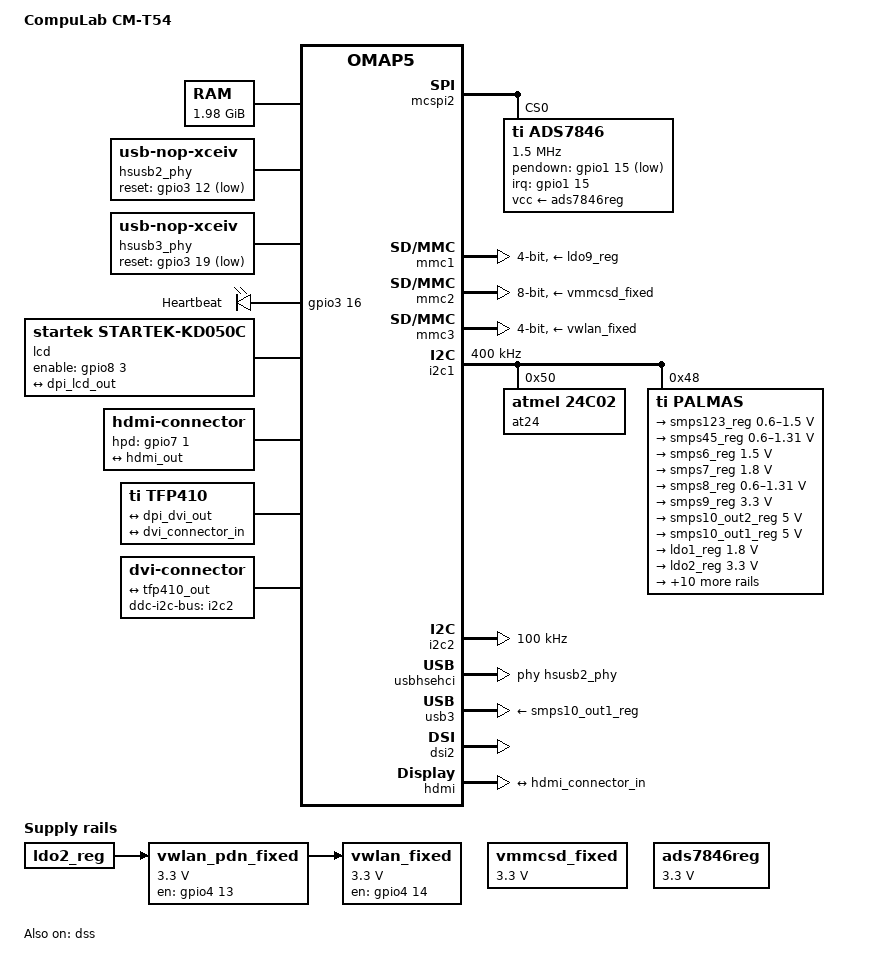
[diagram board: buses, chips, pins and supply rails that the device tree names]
/dts-v1/;
#include "omap5.dtsi"
#include <dt-bindings/interrupt-controller/irq.h>
#include <dt-bindings/interrupt-controller/arm-gic.h>
/ {
	model = "CompuLab CM-T54";
	compatible = "compulab,omap5-cm-t54", "ti,omap5";
	memory@80000000 {
		device_type = "memory";
		reg = <0 0x80000000 0 0x7f000000>;  
	};
	aliases {
		display0 = &hdmi0;
		display1 = &dvi0;
		display2 = &lcd0;
	};
	vmmcsd_fixed: fixed-regulator-mmcsd {
		compatible = "regulator-fixed";
		regulator-name = "vmmcsd_fixed";
		regulator-min-microvolt = <3300000>;
		regulator-max-microvolt = <3300000>;
	};
	vwlan_pdn_fixed: fixed-regulator-vwlan-pdn {
		compatible = "regulator-fixed";
		regulator-name = "vwlan_pdn_fixed";
		regulator-min-microvolt = <3300000>;
		regulator-max-microvolt = <3300000>;
		vin-supply = <&ldo2_reg>;
		gpio = <&gpio4 13 GPIO_ACTIVE_HIGH>;    
		startup-delay-us = <1000>;
		enable-active-high;
	};
	vwlan_fixed: fixed-regulator-vwlan {
		compatible = "regulator-fixed";
		regulator-name = "vwlan_fixed";
		regulator-min-microvolt = <3300000>;
		regulator-max-microvolt = <3300000>;
		vin-supply = <&vwlan_pdn_fixed>;
		gpio = <&gpio4 14 GPIO_ACTIVE_HIGH>;    
		startup-delay-us = <1000>;
		enable-active-high;
	};
	ads7846reg: ads7846-reg {
		compatible = "regulator-fixed";
		regulator-name = "ads7846-reg";
		regulator-min-microvolt = <3300000>;
		regulator-max-microvolt = <3300000>;
	};
	hsusb2_phy: hsusb2-phy-pins {
		compatible = "usb-nop-xceiv";
		reset-gpios = <&gpio3 12 GPIO_ACTIVE_LOW>;  
		#phy-cells = <0>;
	};
	hsusb3_phy: hsusb3_phy {
		compatible = "usb-nop-xceiv";
		reset-gpios = <&gpio3 19 GPIO_ACTIVE_LOW>;  
		#phy-cells = <0>;
	};
	leds {
		compatible = "gpio-leds";
		led1 {
			label = "Heartbeat";
			gpios = <&gpio3 16 GPIO_ACTIVE_HIGH>;  
			linux,default-trigger = "heartbeat";
			default-state = "off";
		};
	};
	lcd0: display {
		compatible = "startek,startek-kd050c", "panel-dpi";
		label = "lcd";
		pinctrl-names = "default";
		pinctrl-0 = <&lcd_pins>;
		enable-gpios = <&gpio8 3 GPIO_ACTIVE_HIGH>;
		panel-timing {
			clock-frequency = <33000000>;
			hactive = <800>;
			vactive = <480>;
			hfront-porch = <40>;
			hback-porch = <40>;
			hsync-len = <43>;
			vback-porch = <29>;
			vfront-porch = <13>;
			vsync-len = <3>;
			hsync-active = <0>;
			vsync-active = <0>;
			de-active = <1>;
			pixelclk-active = <1>;
		};
		port {
			lcd_in: endpoint {
				remote-endpoint = <&dpi_lcd_out>;
			};
		};
	};
	hdmi0: connector0 {
		compatible = "hdmi-connector";
		label = "hdmi";
		type = "a";
		pinctrl-names = "default";
		pinctrl-0 = <&hdmi_conn_pins>;
		hpd-gpios = <&gpio7 1 GPIO_ACTIVE_HIGH>;  
		port {
			hdmi_connector_in: endpoint {
				remote-endpoint = <&hdmi_out>;
			};
		};
	};
	tfp410: encoder0 {
		compatible = "ti,tfp410";
		ports {
			#address-cells = <1>;
			#size-cells = <0>;
			port@0 {
				reg = <0>;
				tfp410_in: endpoint {
					remote-endpoint = <&dpi_dvi_out>;
				};
			};
			port@1 {
				reg = <1>;
				tfp410_out: endpoint {
					remote-endpoint = <&dvi_connector_in>;
				};
			};
		};
	};
	dvi0: connector1 {
		compatible = "dvi-connector";
		label = "dvi";
		digital;
		ddc-i2c-bus = <&i2c2>;
		port {
			dvi_connector_in: endpoint {
				remote-endpoint = <&tfp410_out>;
			};
		};
	};
};
&omap5_pmx_wkup {
	ads7846_pins: ads7846-pins {
		pinctrl-single,pins = <
			OMAP5_IOPAD(0x0042, PIN_INPUT_PULLDOWN | MUX_MODE6)   
		>;
	};
	palmas_sys_nirq_pins: palmas-sys-nirq-pins {
		pinctrl-single,pins = <
			OMAP5_IOPAD(0x068, PIN_INPUT_PULLUP | MUX_MODE0)
		>;
	};
};
&omap5_pmx_core {
	pinctrl-names = "default";
	pinctrl-0 = <
			&led_gpio_pins
			&usbhost_pins
	>;
	led_gpio_pins: led-gpio-pins {
		pinctrl-single,pins = <
			OMAP5_IOPAD(0x00b0, PIN_OUTPUT | MUX_MODE6)  
		>;
	};
	i2c1_pins: i2c1-pins {
		pinctrl-single,pins = <
			OMAP5_IOPAD(0x01f2, PIN_INPUT_PULLUP | MUX_MODE0)  
			OMAP5_IOPAD(0x01f4, PIN_INPUT_PULLUP | MUX_MODE0)  
		>;
	};
	i2c2_pins: i2c2-pins {
		pinctrl-single,pins = <
			OMAP5_IOPAD(0x01b8, PIN_INPUT | MUX_MODE0)  
			OMAP5_IOPAD(0x01ba, PIN_INPUT | MUX_MODE0)  
		>;
	};
	mmc1_pins: mmc1-pins {
		pinctrl-single,pins = <
			OMAP5_IOPAD(0x01e2, PIN_INPUT_PULLUP | MUX_MODE0)  
			OMAP5_IOPAD(0x01e4, PIN_INPUT_PULLUP | MUX_MODE0)  
			OMAP5_IOPAD(0x01e6, PIN_INPUT_PULLUP | MUX_MODE0)  
			OMAP5_IOPAD(0x01e8, PIN_INPUT_PULLUP | MUX_MODE0)  
			OMAP5_IOPAD(0x01ea, PIN_INPUT_PULLUP | MUX_MODE0)  
			OMAP5_IOPAD(0x01ec, PIN_INPUT_PULLUP | MUX_MODE0)  
		>;
	};
	mmc2_pins: mmc2-pins {
		pinctrl-single,pins = <
			OMAP5_IOPAD(0x0040, PIN_INPUT_PULLUP | MUX_MODE0)  
			OMAP5_IOPAD(0x0042, PIN_INPUT_PULLUP | MUX_MODE0)  
			OMAP5_IOPAD(0x0044, PIN_INPUT_PULLUP | MUX_MODE0)  
			OMAP5_IOPAD(0x0046, PIN_INPUT_PULLUP | MUX_MODE0)  
			OMAP5_IOPAD(0x0048, PIN_INPUT_PULLUP | MUX_MODE0)  
			OMAP5_IOPAD(0x004a, PIN_INPUT_PULLUP | MUX_MODE0)  
			OMAP5_IOPAD(0x004c, PIN_INPUT_PULLUP | MUX_MODE0)  
			OMAP5_IOPAD(0x004e, PIN_INPUT_PULLUP | MUX_MODE0)  
			OMAP5_IOPAD(0x0050, PIN_INPUT_PULLUP | MUX_MODE0)  
			OMAP5_IOPAD(0x0052, PIN_INPUT_PULLUP | MUX_MODE0)  
		>;
	};
	mmc3_pins: mmc3-pins {
		pinctrl-single,pins = <
			OMAP5_IOPAD(0x01a4, PIN_INPUT_PULLUP | MUX_MODE0)  
			OMAP5_IOPAD(0x01a6, PIN_INPUT_PULLUP | MUX_MODE0)  
			OMAP5_IOPAD(0x01a8, PIN_INPUT_PULLUP | MUX_MODE0)  
			OMAP5_IOPAD(0x01aa, PIN_INPUT_PULLUP | MUX_MODE0)  
			OMAP5_IOPAD(0x01ac, PIN_INPUT_PULLUP | MUX_MODE0)  
			OMAP5_IOPAD(0x01ae, PIN_INPUT_PULLUP | MUX_MODE0)  
		>;
	};
	wlan_gpios_pins: wlan-gpios-pins {
		pinctrl-single,pins = <
			OMAP5_IOPAD(0x019c, PIN_OUTPUT_PULLDOWN | MUX_MODE6)  
			OMAP5_IOPAD(0x019e, PIN_OUTPUT_PULLDOWN | MUX_MODE6)  
		>;
	};
	usbhost_pins: usbhost-pins {
		pinctrl-single,pins = <
			OMAP5_IOPAD(0x00c4, PIN_INPUT | MUX_MODE0)   
			OMAP5_IOPAD(0x00c6, PIN_INPUT | MUX_MODE0)   
			OMAP5_IOPAD(0x01dc, PIN_INPUT | MUX_MODE0)   
			OMAP5_IOPAD(0x01de, PIN_INPUT | MUX_MODE0)   
			OMAP5_IOPAD(0x00a8, PIN_OUTPUT | MUX_MODE6)  
			OMAP5_IOPAD(0x00b6, PIN_OUTPUT | MUX_MODE6)  
		>;
	};
	dss_hdmi_pins: dss-hdmi-pins {
		pinctrl-single,pins = <
			OMAP5_IOPAD(0x013c, PIN_INPUT | MUX_MODE0)  
			OMAP5_IOPAD(0x0140, PIN_INPUT | MUX_MODE0)  
			OMAP5_IOPAD(0x0142, PIN_INPUT | MUX_MODE0)  
		>;
	};
	lcd_pins: lcd-pins {
		pinctrl-single,pins = <
			OMAP5_IOPAD(0x0172, PIN_OUTPUT_PULLDOWN | MUX_MODE6)  
		>;
	};
	hdmi_conn_pins: hdmi-conn-pins {
		pinctrl-single,pins = <
			OMAP5_IOPAD(0x013e, PIN_INPUT | MUX_MODE6)  
		>;
	};
	dss_dpi_pins: dss-dpi-pins {
		pinctrl-single,pins = <
			OMAP5_IOPAD(0x0104, PIN_OUTPUT | MUX_MODE3)  
			OMAP5_IOPAD(0x0106, PIN_OUTPUT | MUX_MODE3)  
			OMAP5_IOPAD(0x0108, PIN_OUTPUT | MUX_MODE3)  
			OMAP5_IOPAD(0x010a, PIN_OUTPUT | MUX_MODE3)  
			OMAP5_IOPAD(0x010c, PIN_OUTPUT | MUX_MODE3)  
			OMAP5_IOPAD(0x010e, PIN_OUTPUT | MUX_MODE3)  
			OMAP5_IOPAD(0x0110, PIN_OUTPUT | MUX_MODE3)  
			OMAP5_IOPAD(0x0112, PIN_OUTPUT | MUX_MODE3)  
			OMAP5_IOPAD(0x0114, PIN_OUTPUT | MUX_MODE3)  
			OMAP5_IOPAD(0x0116, PIN_OUTPUT | MUX_MODE3)  
			OMAP5_IOPAD(0x0118, PIN_OUTPUT | MUX_MODE3)  
			OMAP5_IOPAD(0x011a, PIN_OUTPUT | MUX_MODE3)  
			OMAP5_IOPAD(0x011c, PIN_OUTPUT | MUX_MODE3)  
			OMAP5_IOPAD(0x011e, PIN_OUTPUT | MUX_MODE3)  
			OMAP5_IOPAD(0x0120, PIN_OUTPUT | MUX_MODE3)  
			OMAP5_IOPAD(0x0122, PIN_OUTPUT | MUX_MODE3)  
			OMAP5_IOPAD(0x0124, PIN_OUTPUT | MUX_MODE3)  
			OMAP5_IOPAD(0x0126, PIN_OUTPUT | MUX_MODE3)  
			OMAP5_IOPAD(0x0128, PIN_OUTPUT | MUX_MODE3)  
			OMAP5_IOPAD(0x012a, PIN_OUTPUT | MUX_MODE3)  
			OMAP5_IOPAD(0x012c, PIN_OUTPUT | MUX_MODE3)  
			OMAP5_IOPAD(0x012e, PIN_OUTPUT | MUX_MODE3)  
			OMAP5_IOPAD(0x0130, PIN_OUTPUT | MUX_MODE3)  
			OMAP5_IOPAD(0x0132, PIN_OUTPUT | MUX_MODE3)  
			OMAP5_IOPAD(0x0134, PIN_OUTPUT | MUX_MODE3)  
			OMAP5_IOPAD(0x0136, PIN_OUTPUT | MUX_MODE3)  
			OMAP5_IOPAD(0x0138, PIN_OUTPUT | MUX_MODE3)  
			OMAP5_IOPAD(0x013a, PIN_OUTPUT | MUX_MODE3)  
		>;
	};
	mcspi2_pins: mcspi1-pins {
		pinctrl-single,pins = <
			OMAP5_IOPAD(0x00fc, PIN_INPUT | MUX_MODE0)  
			OMAP5_IOPAD(0x00fe, PIN_INPUT | MUX_MODE0)  
			OMAP5_IOPAD(0x0100, PIN_INPUT | MUX_MODE0)  
			OMAP5_IOPAD(0x0102, PIN_INPUT | MUX_MODE0)  
		>;
	};
};
&mcspi2 {
	pinctrl-names = "default";
	pinctrl-0 = <&mcspi2_pins>;
	ads7846@0 {
		pinctrl-names = "default";
		pinctrl-0 = <&ads7846_pins>;
		compatible = "ti,ads7846";
		vcc-supply = <&ads7846reg>;
		reg = <0>;				 
		spi-max-frequency = <1500000>;
		interrupt-parent = <&gpio1>;
		interrupts = <15 0>;			 
		pendown-gpio = <&gpio1 15 GPIO_ACTIVE_LOW>;
		ti,x-min = /bits/ 16 <0x0>;
		ti,x-max = /bits/ 16 <0x0fff>;
		ti,y-min = /bits/ 16 <0x0>;
		ti,y-max = /bits/ 16 <0x0fff>;
		ti,x-plate-ohms = /bits/ 16 <180>;
		ti,pressure-max = /bits/ 16 <255>;
		ti,debounce-max = /bits/ 16 <30>;
		ti,debounce-tol = /bits/ 16 <10>;
		ti,debounce-rep = /bits/ 16 <1>;
		wakeup-source;
	};
};
&mmc1 {
	pinctrl-names = "default";
	pinctrl-0 = <&mmc1_pins>;
	vmmc-supply = <&ldo9_reg>;
	bus-width = <4>;
};
&mmc2 {
	pinctrl-names = "default";
	pinctrl-0 = <&mmc2_pins>;
	vmmc-supply = <&vmmcsd_fixed>;
	bus-width = <8>;
	ti,non-removable;
};
&mmc3 {
	pinctrl-names = "default";
	pinctrl-0 = <
		&mmc3_pins
		&wlan_gpios_pins
	>;
	vmmc-supply = <&vwlan_fixed>;
	bus-width = <4>;
	ti,non-removable;
};
&mmc4 {
	status = "disabled";
};
&mmc5 {
	status = "disabled";
};
&i2c1 {
	pinctrl-names = "default";
	pinctrl-0 = <&i2c1_pins>;
	clock-frequency = <400000>;
	at24@50 {
		compatible = "atmel,24c02";
		pagesize = <16>;
		reg = <0x50>;
	};
	palmas: palmas@48 {
		compatible = "ti,palmas";
		reg = <0x48>;
		pinctrl-0 = <&palmas_sys_nirq_pins>;
		pinctrl-names = "default";
		interrupts = <GIC_SPI 7 IRQ_TYPE_LEVEL_LOW>;
		interrupt-controller;
		#interrupt-cells = <2>;
		ti,system-power-controller;
		extcon_usb3: palmas_usb {
			compatible = "ti,palmas-usb-vid";
			ti,enable-vbus-detection;
			ti,enable-id-detection;
			ti,wakeup;
		};
		rtc {
			compatible = "ti,palmas-rtc";
			interrupt-parent = <&palmas>;
			interrupts = <8 IRQ_TYPE_NONE>;
		};
		palmas_pmic {
			compatible = "ti,palmas-pmic";
			interrupt-parent = <&palmas>;
			interrupts = <14 IRQ_TYPE_NONE>;
			interrupt-names = "short-irq";
			ti,ldo6-vibrator;
			regulators {
				smps123_reg: smps123 {
					regulator-name = "smps123";
					regulator-min-microvolt = < 600000>;
					regulator-max-microvolt = <1500000>;
					regulator-always-on;
					regulator-boot-on;
				};
				smps45_reg: smps45 {
					regulator-name = "smps45";
					regulator-min-microvolt = < 600000>;
					regulator-max-microvolt = <1310000>;
					regulator-always-on;
					regulator-boot-on;
				};
				smps6_reg: smps6 {
					regulator-name = "smps6";
					regulator-min-microvolt = <1500000>;
					regulator-max-microvolt = <1500000>;
					regulator-always-on;
					regulator-boot-on;
				};
				smps7_reg: smps7 {
					regulator-name = "smps7";
					regulator-min-microvolt = <1800000>;
					regulator-max-microvolt = <1800000>;
					regulator-always-on;
					regulator-boot-on;
				};
				smps8_reg: smps8 {
					regulator-name = "smps8";
					regulator-min-microvolt = < 600000>;
					regulator-max-microvolt = <1310000>;
					regulator-always-on;
					regulator-boot-on;
				};
				smps9_reg: smps9 {
					regulator-name = "smps9";
					regulator-min-microvolt = <3300000>;
					regulator-max-microvolt = <3300000>;
					ti,smps-range = <0x80>;
					regulator-always-on;
					regulator-boot-on;
				};
				smps10_out2_reg: smps10_out2 {
					regulator-name = "smps10_out2";
					regulator-min-microvolt = <5000000>;
					regulator-max-microvolt = <5000000>;
					regulator-always-on;
					regulator-boot-on;
				};
				smps10_out1_reg: smps10_out1 {
					regulator-name = "smps10_out1";
					regulator-min-microvolt = <5000000>;
					regulator-max-microvolt = <5000000>;
				};
				ldo1_reg: ldo1 {
					regulator-name = "ldo1";
					regulator-min-microvolt = <1800000>;
					regulator-max-microvolt = <1800000>;
				};
				ldo2_reg: ldo2 {
					regulator-name = "ldo2";
					regulator-min-microvolt = <3300000>;
					regulator-max-microvolt = <3300000>;
					startup-delay-us = <1000>;
				};
				ldo3_reg: ldo3 {
					regulator-name = "ldo3";
					regulator-min-microvolt = <1500000>;
					regulator-max-microvolt = <1500000>;
					regulator-always-on;
					regulator-boot-on;
				};
				ldo4_reg: ldo4 {
					regulator-name = "ldo4";
					regulator-min-microvolt = <1800000>;
					regulator-max-microvolt = <1800000>;
				};
				ldo5_reg: ldo5 {
					regulator-name = "ldo5";
					regulator-min-microvolt = <1800000>;
					regulator-max-microvolt = <1800000>;
					regulator-always-on;
					regulator-boot-on;
				};
				ldo6_reg: ldo6 {
					regulator-name = "ldo6";
					regulator-min-microvolt = <1200000>;
					regulator-max-microvolt = <1200000>;
					regulator-always-on;
					regulator-boot-on;
				};
				ldo7_reg: ldo7 {
					regulator-name = "ldo7";
					regulator-min-microvolt = <2000000>;
					regulator-max-microvolt = <2000000>;
					status = "disabled";
				};
				ldo8_reg: ldo8 {
					regulator-name = "ldo8";
					regulator-min-microvolt = <3000000>;
					regulator-max-microvolt = <3000000>;
					regulator-always-on;
					regulator-boot-on;
				};
				ldo9_reg: ldo9 {
					regulator-name = "ldo9";
					regulator-min-microvolt = <1800000>;
					regulator-max-microvolt = <3000000>;
					regulator-boot-on;
				};
				ldoln_reg: ldoln {
					regulator-name = "ldoln";
					regulator-min-microvolt = <1800000>;
					regulator-max-microvolt = <1800000>;
					regulator-always-on;
					regulator-boot-on;
				};
				ldousb_reg: ldousb {
					regulator-name = "ldousb";
					regulator-min-microvolt = <3250000>;
					regulator-max-microvolt = <3250000>;
					regulator-always-on;
					regulator-boot-on;
				};
				regen3_reg: regen3 {
					regulator-name = "regen3";
					regulator-always-on;
					regulator-boot-on;
				};
			};
		};
	};
};
&i2c2 {
	pinctrl-names = "default";
	pinctrl-0 = <&i2c2_pins>;
	clock-frequency = <100000>;
};
&usbhshost {
	port2-mode = "ehci-hsic";
	port3-mode = "ehci-hsic";
};
&usbhsehci {
	phys = <0 &hsusb2_phy &hsusb3_phy>;
};
&usb3 {
	extcon = <&extcon_usb3>;
	vbus-supply = <&smps10_out1_reg>;
};
&cpu0 {
	cpu0-supply = <&smps123_reg>;
};
&dss {
	status = "okay";
	pinctrl-names = "default";
	pinctrl-0 = <&dss_dpi_pins>;
	port {
		#address-cells = <1>;
		#size-cells = <0>;
		dpi_dvi_out: endpoint@0 {
			reg = <0>;
			remote-endpoint = <&tfp410_in>;
			data-lines = <24>;
		};
		dpi_lcd_out: endpoint@1 {
			reg = <1>;
			remote-endpoint = <&lcd_in>;
			data-lines = <24>;
		};
	};
};
&dsi2 {
	status = "okay";
	vdd-supply = <&ldo4_reg>;
};
&hdmi {
	status = "okay";
	vdda-supply = <&ldo4_reg>;
	pinctrl-names = "default";
	pinctrl-0 = <&dss_hdmi_pins>;
	port {
		hdmi_out: endpoint {
			remote-endpoint = <&hdmi_connector_in>;
			lanes = <1 0 3 2 5 4 7 6>;
		};
	};
};
